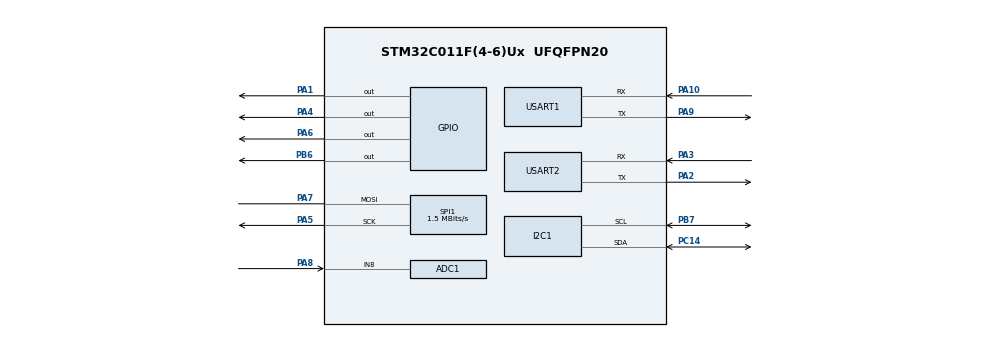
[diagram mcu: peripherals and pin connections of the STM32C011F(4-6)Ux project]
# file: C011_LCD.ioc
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ADC1.NbrOfConversionFlag=0
ADC1.SelectedChannel=ADC_CHANNEL_8
ADC1.master=1
I2C1.Timing=0x10805D88
Mcu.Family=STM32C0
Mcu.Name=STM32C011F(4-6)Ux
Mcu.Package=UFQFPN20
PA1.Signal=GPIO_Output
PA10\ [PA12].Mode=Asynchronous
PA10\ [PA12].Signal=USART1_RX
PA13.Mode=Serial_Wire
PA13.Signal=DEBUG_SWDIO
PA14-BOOT0.Mode=Serial_Wire
PA14-BOOT0.Signal=DEBUG_SWCLK
PA2.Mode=Asynchronous
PA2.Signal=USART2_TX
PA3.Mode=Asynchronous
PA3.Signal=USART2_RX
PA4.Signal=GPIO_Output
PA5.Mode=Simplex_Bidirectional_Master
PA5.Signal=SPI1_SCK
PA6.Signal=GPIO_Output
PA7.Mode=Simplex_Bidirectional_Master
PA7.Signal=SPI1_MOSI
PA8.Signal=SharedAnalog_PA8
PA9\ [PA11].Mode=Asynchronous
PA9\ [PA11].Signal=USART1_TX
PB6.Signal=GPIO_Output
PB7.Mode=I2C
PB7.Signal=I2C1_SCL
PC14-OSCX_IN\ (PC14).Mode=I2C
PC14-OSCX_IN\ (PC14).Signal=I2C1_SDA
ProjectManager.HeapSize=0x200
ProjectManager.StackSize=0x400
ProjectManager.TargetToolchain=STM32CubeIDE
RCC.ADCFreq_Value=48000000
RCC.AHBFreq_Value=48000000
RCC.CortexFreq_Value=48000000
RCC.EXTERNAL_CLOCK_VALUE=12288000
RCC.HCLKFreq_Value=48000000
RCC.HSE_VALUE=8000000
RCC.HSISYSCLKDivider=RCC_HSI_DIV1
RCC.HSI_VALUE=48000000
RCC.LSE_VALUE=32768
RCC.SYSCLKFreq_VALUE=48000000
SH.SharedAnalog_PA8.0=GPIO_Analog
SH.SharedAnalog_PA8.1=ADC1_IN8,IN8
SPI1.BaudRatePrescaler=SPI_BAUDRATEPRESCALER_32
SPI1.CalculateBaudRate=1.5 MBits/s
SPI1.Direction=SPI_DIRECTION_1LINE
SPI1.Mode=SPI_MODE_MASTER
SPI1.NSSPMode=SPI_NSS_PULSE_DISABLE
SPI1.VirtualType=VM_MASTER
USART1.VirtualMode-Asynchronous=VM_ASYNC
USART2.VirtualMode-Asynchronous=VM_ASYNC
VP_RTC_VS_RTC_Activate.Mode=RTC_Enabled
VP_SYS_VS_PINREMAP.Mode=PINREMAP
VP_SYS_VS_PINREMAP_10_12.Mode=PINREMAP_10_12
board=STM32C0116-DK

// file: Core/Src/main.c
/* USER CODE BEGIN Header */
/**
  ******************************************************************************
  * @file           : main.c
  * @brief          : Main program body
  ******************************************************************************
  * @attention
  *
  * Copyright (c) 2026 STMicroelectronics.
  * All rights reserved.
  *
  * This software is licensed under terms that can be found in the LICENSE file
  * in the root directory of this software component.
  * If no LICENSE file comes with this software, it is provided AS-IS.
  *
  ******************************************************************************
  */
/* USER CODE END Header */
#include "main.h"

/* USER CODE BEGIN Includes */

#include "app.h"
#include "pc_uart.h"

/* USER CODE END Includes */

ADC_HandleTypeDef hadc1;

I2C_HandleTypeDef hi2c1;

RTC_HandleTypeDef hrtc;

SPI_HandleTypeDef hspi1;

UART_HandleTypeDef huart1;
UART_HandleTypeDef huart2;

void SystemClock_Config(void);
static void MX_GPIO_Init(void);
static void MX_SPI1_Init(void);
static void MX_ADC1_Init(void);
static void MX_I2C1_Init(void);
static void MX_USART2_UART_Init(void);
static void MX_RTC_Init(void);
static void MX_USART1_UART_Init(void);

int main(void)
{

  /* MCU Configuration--------------------------------------------------------*/

  /* Reset of all peripherals, Initializes the Flash interface and the Systick. */
  HAL_Init();

  /* Configure the system clock */
  SystemClock_Config();

  /* Initialize all configured peripherals */
  MX_GPIO_Init();
  MX_SPI1_Init();
  MX_ADC1_Init();
  MX_I2C1_Init();
  MX_USART2_UART_Init();
  MX_RTC_Init();
  MX_USART1_UART_Init();
  /* USER CODE BEGIN 2 */

  APP_Init();

  /* USER CODE END 2 */

  /* Infinite loop */
  while (1)
  {

    /* USER CODE BEGIN 3 */

      APP_Loop();

    /* USER CODE END 3 */
}

void SystemClock_Config(void)
{
  RCC_OscInitTypeDef RCC_OscInitStruct = {0};
  RCC_ClkInitTypeDef RCC_ClkInitStruct = {0};

  __HAL_FLASH_SET_LATENCY(FLASH_LATENCY_1);

  /** Initializes the RCC Oscillators according to the specified parameters
  * in the RCC_OscInitTypeDef structure.
  */
  RCC_OscInitStruct.OscillatorType = RCC_OSCILLATORTYPE_HSI|RCC_OSCILLATORTYPE_LSI;
  RCC_OscInitStruct.HSIState = RCC_HSI_ON;
  RCC_OscInitStruct.HSIDiv = RCC_HSI_DIV1;
  RCC_OscInitStruct.HSICalibrationValue = RCC_HSICALIBRATION_DEFAULT;
  RCC_OscInitStruct.LSIState = RCC_LSI_ON;
  if (HAL_RCC_OscConfig(&RCC_OscInitStruct) != HAL_OK)
  {
    Error_Handler();
  }

  /** Initializes the CPU, AHB and APB buses clocks
  */
  RCC_ClkInitStruct.ClockType = RCC_CLOCKTYPE_HCLK|RCC_CLOCKTYPE_SYSCLK
                              |RCC_CLOCKTYPE_PCLK1;
  RCC_ClkInitStruct.SYSCLKSource = RCC_SYSCLKSOURCE_HSI;
  RCC_ClkInitStruct.SYSCLKDivider = RCC_SYSCLK_DIV1;
  RCC_ClkInitStruct.AHBCLKDivider = RCC_HCLK_DIV1;
  RCC_ClkInitStruct.APB1CLKDivider = RCC_APB1_DIV1;

  if (HAL_RCC_ClockConfig(&RCC_ClkInitStruct, FLASH_LATENCY_1) != HAL_OK)
  {
    Error_Handler();
  }
}

static void MX_ADC1_Init(void)
{

  ADC_ChannelConfTypeDef sConfig = {0};

  /** Configure the global features of the ADC (Clock, Resolution, Data Alignment and number of conversion)
  */
  hadc1.Instance = ADC1;
  hadc1.Init.ClockPrescaler = ADC_CLOCK_SYNC_PCLK_DIV2;
  hadc1.Init.Resolution = ADC_RESOLUTION_12B;
  hadc1.Init.DataAlign = ADC_DATAALIGN_RIGHT;
  hadc1.Init.ScanConvMode = ADC_SCAN_SEQ_FIXED;
  hadc1.Init.EOCSelection = ADC_EOC_SINGLE_CONV;
  hadc1.Init.LowPowerAutoWait = DISABLE;
  hadc1.Init.LowPowerAutoPowerOff = DISABLE;
  hadc1.Init.ContinuousConvMode = DISABLE;
  hadc1.Init.NbrOfConversion = 1;
  hadc1.Init.DiscontinuousConvMode = DISABLE;
  hadc1.Init.ExternalTrigConv = ADC_SOFTWARE_START;
  hadc1.Init.ExternalTrigConvEdge = ADC_EXTERNALTRIGCONVEDGE_NONE;
  hadc1.Init.DMAContinuousRequests = DISABLE;
  hadc1.Init.Overrun = ADC_OVR_DATA_PRESERVED;
  hadc1.Init.SamplingTimeCommon1 = ADC_SAMPLETIME_1CYCLE_5;
  hadc1.Init.OversamplingMode = DISABLE;
  hadc1.Init.TriggerFrequencyMode = ADC_TRIGGER_FREQ_HIGH;
  if (HAL_ADC_Init(&hadc1) != HAL_OK)
  {
    Error_Handler();
  }

  /** Configure Regular Channel
  */
  sConfig.Channel = ADC_CHANNEL_8;
  sConfig.Rank = ADC_RANK_CHANNEL_NUMBER;
  if (HAL_ADC_ConfigChannel(&hadc1, &sConfig) != HAL_OK)
  {
    Error_Handler();
  }

}

static void MX_I2C1_Init(void)
{

  hi2c1.Instance = I2C1;
  hi2c1.Init.Timing = 0x10805D88;
  hi2c1.Init.OwnAddress1 = 0;
  hi2c1.Init.AddressingMode = I2C_ADDRESSINGMODE_7BIT;
  hi2c1.Init.DualAddressMode = I2C_DUALADDRESS_DISABLE;
  hi2c1.Init.OwnAddress2 = 0;
  hi2c1.Init.OwnAddress2Masks = I2C_OA2_NOMASK;
  hi2c1.Init.GeneralCallMode = I2C_GENERALCALL_DISABLE;
  hi2c1.Init.NoStretchMode = I2C_NOSTRETCH_DISABLE;
  if (HAL_I2C_Init(&hi2c1) != HAL_OK)
  {
    Error_Handler();
  }

  /** Configure Analogue filter
  */
  if (HAL_I2CEx_ConfigAnalogFilter(&hi2c1, I2C_ANALOGFILTER_ENABLE) != HAL_OK)
  {
    Error_Handler();
  }

  /** Configure Digital filter
  */
  if (HAL_I2CEx_ConfigDigitalFilter(&hi2c1, 0) != HAL_OK)
  {
    Error_Handler();
  }

}

static void MX_RTC_Init(void)
{

  /** Initialize RTC Only
  */
  hrtc.Instance = RTC;
  hrtc.Init.HourFormat = RTC_HOURFORMAT_24;
  hrtc.Init.AsynchPrediv = 127;
  hrtc.Init.SynchPrediv = 255;
  hrtc.Init.OutPut = RTC_OUTPUT_DISABLE;
  hrtc.Init.OutPutRemap = RTC_OUTPUT_REMAP_NONE;
  hrtc.Init.OutPutPolarity = RTC_OUTPUT_POLARITY_HIGH;
  hrtc.Init.OutPutType = RTC_OUTPUT_TYPE_OPENDRAIN;
  hrtc.Init.OutPutPullUp = RTC_OUTPUT_PULLUP_NONE;
  if (HAL_RTC_Init(&hrtc) != HAL_OK)
  {
    Error_Handler();
  }

}

static void MX_SPI1_Init(void)
{

  /* SPI1 parameter configuration*/
  hspi1.Instance = SPI1;
  hspi1.Init.Mode = SPI_MODE_MASTER;
  hspi1.Init.Direction = SPI_DIRECTION_1LINE;
  hspi1.Init.DataSize = SPI_DATASIZE_8BIT;
  hspi1.Init.CLKPolarity = SPI_POLARITY_LOW;
  hspi1.Init.CLKPhase = SPI_PHASE_1EDGE;
  hspi1.Init.NSS = SPI_NSS_SOFT;
  hspi1.Init.BaudRatePrescaler = SPI_BAUDRATEPRESCALER_32;
  hspi1.Init.FirstBit = SPI_FIRSTBIT_MSB;
  hspi1.Init.TIMode = SPI_TIMODE_DISABLE;
  hspi1.Init.CRCCalculation = SPI_CRCCALCULATION_DISABLE;
  hspi1.Init.CRCPolynomial = 7;
  hspi1.Init.CRCLength = SPI_CRC_LENGTH_DATASIZE;
  hspi1.Init.NSSPMode = SPI_NSS_PULSE_DISABLE;
  if (HAL_SPI_Init(&hspi1) != HAL_OK)
  {
    Error_Handler();
  }

}

static void MX_USART1_UART_Init(void)
{

  huart1.Instance = USART1;
  huart1.Init.BaudRate = 115200;
  huart1.Init.WordLength = UART_WORDLENGTH_8B;
  huart1.Init.StopBits = UART_STOPBITS_1;
  huart1.Init.Parity = UART_PARITY_NONE;
  huart1.Init.Mode = UART_MODE_TX_RX;
  huart1.Init.HwFlowCtl = UART_HWCONTROL_NONE;
  huart1.Init.OverSampling = UART_OVERSAMPLING_16;
  huart1.Init.OneBitSampling = UART_ONE_BIT_SAMPLE_DISABLE;
  huart1.Init.ClockPrescaler = UART_PRESCALER_DIV1;
  huart1.AdvancedInit.AdvFeatureInit = UART_ADVFEATURE_NO_INIT;
  if (HAL_UART_Init(&huart1) != HAL_OK)
  {
    Error_Handler();
  }
  if (HAL_UARTEx_SetTxFifoThreshold(&huart1, UART_TXFIFO_THRESHOLD_1_8) != HAL_OK)
  {
    Error_Handler();
  }
  if (HAL_UARTEx_SetRxFifoThreshold(&huart1, UART_RXFIFO_THRESHOLD_1_8) != HAL_OK)
  {
    Error_Handler();
  }
  if (HAL_UARTEx_DisableFifoMode(&huart1) != HAL_OK)
  {
    Error_Handler();
  }

}

static void MX_USART2_UART_Init(void)
{

  huart2.Instance = USART2;
  huart2.Init.BaudRate = 115200;
  huart2.Init.WordLength = UART_WORDLENGTH_8B;
  huart2.Init.StopBits = UART_STOPBITS_1;
  huart2.Init.Parity = UART_PARITY_NONE;
  huart2.Init.Mode = UART_MODE_TX_RX;
  huart2.Init.HwFlowCtl = UART_HWCONTROL_NONE;
  huart2.Init.OverSampling = UART_OVERSAMPLING_16;
  huart2.Init.OneBitSampling = UART_ONE_BIT_SAMPLE_DISABLE;
  huart2.Init.ClockPrescaler = UART_PRESCALER_DIV1;
  huart2.AdvancedInit.AdvFeatureInit = UART_ADVFEATURE_NO_INIT;
  if (HAL_UART_Init(&huart2) != HAL_OK)
  {
    Error_Handler();
  }

}

static void MX_GPIO_Init(void)
{
  GPIO_InitTypeDef GPIO_InitStruct = {0};

  /* GPIO Ports Clock Enable */
  __HAL_RCC_GPIOA_CLK_ENABLE();
  __HAL_RCC_GPIOB_CLK_ENABLE();
  __HAL_RCC_GPIOC_CLK_ENABLE();

  /*Configure GPIO pin Output Level */
  HAL_GPIO_WritePin(GPIOA, GPIO_PIN_1|GPIO_PIN_4|GPIO_PIN_6, GPIO_PIN_RESET);

  /*Configure GPIO pin Output Level */
  HAL_GPIO_WritePin(GPIOB, GPIO_PIN_6, GPIO_PIN_RESET);

  /*Configure GPIO pins : PA1 PA4 PA6 */
  GPIO_InitStruct.Pin = GPIO_PIN_1|GPIO_PIN_4|GPIO_PIN_6;
  GPIO_InitStruct.Mode = GPIO_MODE_OUTPUT_PP;
  GPIO_InitStruct.Pull = GPIO_NOPULL;
  GPIO_InitStruct.Speed = GPIO_SPEED_FREQ_LOW;
  HAL_GPIO_Init(GPIOA, &GPIO_InitStruct);

  /*Configure GPIO pin : PB6 */
  GPIO_InitStruct.Pin = GPIO_PIN_6;
  GPIO_InitStruct.Mode = GPIO_MODE_OUTPUT_PP;
  GPIO_InitStruct.Pull = GPIO_NOPULL;
  GPIO_InitStruct.Speed = GPIO_SPEED_FREQ_LOW;
  HAL_GPIO_Init(GPIOB, &GPIO_InitStruct);

}

void Error_Handler(void)
{
  __disable_irq();
  while (1)
  {
  }
}
